# YTM32B1HA0 register map
Vendor: YTMicro; File version: 1.0
YTM32B1HA0 YTMicro Microcontroller
CPU: little endian, MPU, FPU, 2 interrupt priority bits
Registers are 32-bit, read-write, reset 0x0 unless marked. A register's access mark holds for its fields unless they carry their own. Offsets are from the block's base; lines under a group give offsets from that group; [hi:lo] are bit positions; {n}, {i} and the like mark numbered series; 'fields as' and 'values as' point back to an identical list; <NAME> marks a mode.

## Memory map
0x40020000 DMA0 size 0x1200
0x40040000 EFM size 0x400 — Embedded FLASH Module
0x40044000 GPIOA size 0xFF
0x40044100 GPIOB size 0xFF
0x40044200 GPIOC size 0xFF
0x40044300 GPIOD size 0xFF
0x40044400 GPIOE size 0xFF
0x40048000 PCTRLA size 0x80 — PORT Control
0x4004C000 PCTRLB size 0x80 — PORT Control
0x40050000 PCTRLC size 0x80 — PORT Control
0x40054000 PCTRLD size 0x80 — PORT Control
0x40058000 PCTRLE size 0x80 — PORT Control
{0x4006C000+0x4000*n} LINFlexD{n} size 0xA0 (n=0..9)
0x40094000 I2C0 size 0x120
0x40098000 I2C1 size 0x120
0x4009C000 I2C2 size 0x120
0x400A0000 I2C3 size 0x120
0x400A4000 I2C4 size 0x120
{0x400A8000+0x4000*n} SPI{n} size 0x28 (n=0..7)
{0x400D0000+0x4000*n} CAN{n} size 0xC08 (n=0..7) — FlexCAN module
0x40100000 ADC0 size 0xBC
0x40104000 ADC1 size 0xBC
0x4010C000 ACMP0 size 0x24 — Analog comparator module
0x40110000 ACMP1 size 0x24 — Analog comparator module
0x40118000 PTU0 size 0x198 — Programmable Trigger Unit
0x4011C000 PTU1 size 0x198 — Programmable Trigger Unit
0x40120000 TMU size 0x80 — Trigger Multiplexer Module
0x40124000 eTMR0 size 0x268 — Enhanced timer
0x40128000 eTMR1 size 0x268 — Enhanced timer
0x4012C000 eTMR2 size 0x268 — Enhanced timer
0x40130000 eTMR3 size 0x268 — Enhanced timer
0x40134000 eTMR4 size 0x268 — Enhanced timer
0x40138000 eTMR5 size 0x268 — Enhanced timer
0x40144000 MPWM0
0x40148000 MPWM1
0x4014C000 MPWM2
0x40150000 TMR0 size 0x4C
0x40154000 TMR1 size 0x4C
0x40160000 SENT0 size 0x110 — Single Edge Nibble Transmission
0x40164000 SENT1 size 0x110 — Single Edge Nibble Transmission
0x40168000 pTMR0 size 0x140 — Periodic timer
0x4016C000 pTMR1 size 0x140 — Periodic timer
0x40170000 pTMR2 size 0x140 — Periodic timer
0x40174000 lpTMR0 size 0x18 — Low Power Timer
0x40180000 RTC size 0x20
0x40184000 REGFILE size 0x20
0x40188000 WKU size 0x4C — Wake-up Unit
0x40194000 PCRC size 0x10 — Cyclic Redundancy Check
0x40198000 TRNG size 0x60
0x4019C000 HCU size 0xB8 — Hardware Cryptography Unit
0x401A0000 QSPI size 0x158 — Quad Serial Peripheral Interface
0x401A8000 WDG size 0x1C — Watchdog module
0x401C0000 FMU0 size 0x190 — Chip fault collect and process
0x401C4000 INTM size 0x12C — Interrupt Monitor
0x401C8000 EMU size 0x16C — ECC Management Unit
0x401CC000 SAI0 size 0x100
0x401D0000 SAI1 size 0x100
0x401E4000 ENET — Ethernet Quality-of-Service
0x401EC000 CIM size 0xC4 — Chip Integration Module
0x401F0000 SCU size 0x6C — System Clock Unit of Microcontroller
0x401F4000 IPC size 0x1FC — IP Control
0x401F8000 PCU size 0x20 — Power control unit
0x401FC000 RCU size 0x8 — Reset Contru Unit of Microcontroller

## REGFILE
Base 0x40184000; register names take the prefix REGFILE_
{0x0+4i} DR{i} (i=0..7)
  [31:0] DATA — The data value stored at register file block. The register is only reseted by POR.

## GPIOA
Base 0x40044000; register names take the prefix GPIOA_
0x00 PDOR
  [31:0] PDO — When configured for general-purpose output, it shows the logic level on the corresponding pin.
0x04 PSOR wo
  [31:0] PSO — Writing to this register will update the contents of the corresponding bit in PDOR.
    0=No change; 1=Corresponding bit in PDOR is set to logic 1
0x08 PCOR wo
  [31:0] PCO — Writing to this register will update the contents of the corresponding bit in PDOR.
    0=No change; 1=Corresponding bit in PDOR is set to logic 0
0x0C PTOR wo
  [31:0] PTO — Writing to this register will update the contents of the corresponding bit in PDOR.
    0=No change; 1=Corresponding bit in PDOR is set to the inverse of its existing logic state
0x10 PDIR ro
  [31:0] PDI — When configured for digital function, it shows the logic level on the corresponding pin. ewline When configured for analog function, it always reads 0.
0x14 POER
  [31:0] POE — Configure the corresponding pin for output.
    0=Port output disable; 1=Port output enable
0x18 PIER reset 0xFFFFFFFF
  [31:0] PIE — Configure the corresponding pin for input.
    0=Port input enable; 1=Port input disable
0x1C PIFR
  [31:0] PIF — Indicate the detection for the defined event in PCTRL[IRQC] of the corresponding pin.
    0=No event detected; 1=The event defined in PCTRL[IRQC] is detected
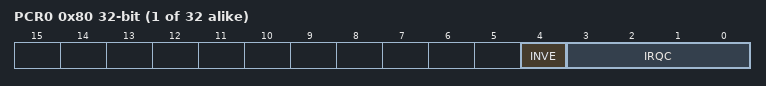
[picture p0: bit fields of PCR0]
{0x80+4i} PCR{i} (i=0..31)
  [4] INVE — Invert the input logic level when configured for digital function.
  [3:0] IRQC
    0=Disabled; 1=DMA request on rising edge; 2=DMA request on falling edge; 3=DMA request on either edge; 8=Interrupt when logic 0; 9=Interrupt on rising-edge; 10=Interrupt on falling-edge; 11=Interrupt on either edge; 12=Interrupt when logic 1

## GPIOB
Base 0x40044100; register names take the prefix GPIOB_
Registers as GPIOA.

## GPIOC
Base 0x40044200; register names take the prefix GPIOC_
Registers as GPIOA.

## GPIOD
Base 0x40044300; register names take the prefix GPIOD_
Registers as GPIOA.

## GPIOE
Base 0x40044400; register names take the prefix GPIOE_
Registers as GPIOA.

## Licence text in the file
YTMicro Microcontroller all rights reserved.
